# STM32F427 register map
File version: 1.4
CPU: CM4 r0p1, little endian, MPU, FPU, 4 interrupt priority bits
Registers are 32-bit, read-write, reset 0x0 unless marked. A register's access mark holds for its fields unless they carry their own. Offsets are from the block's base; [hi:lo] are bit positions.

## DMA2D
Base 0x4002B000
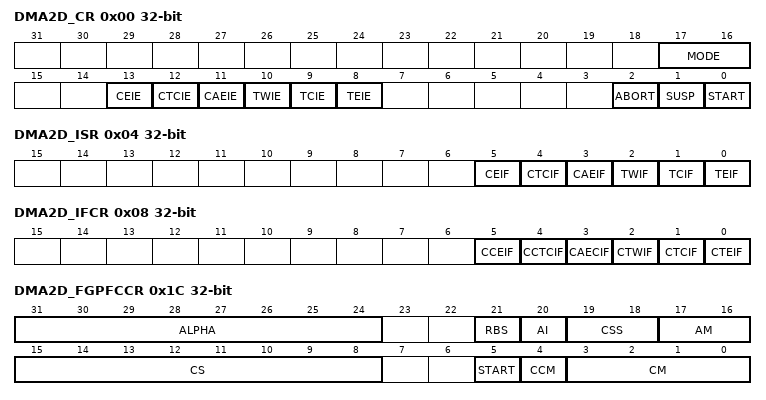
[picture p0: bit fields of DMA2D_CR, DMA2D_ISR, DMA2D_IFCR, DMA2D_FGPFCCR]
0x00 DMA2D_CR — DMA2D control register
  [17:16] MODE — DMA2D mode This bit is set and cleared by software. It cannot be modified while a transfer is ongoing.
  [13] CEIE — Configuration Error Interrupt Enable This bit is set and cleared by software.
  [12] CTCIE — CLUT transfer complete interrupt enable This bit is set and cleared by software.
  [11] CAEIE — CLUT access error interrupt enable This bit is set and cleared by software.
  [10] TWIE — Transfer watermark interrupt enable This bit is set and cleared by software.
  [9] TCIE — Transfer complete interrupt enable This bit is set and cleared by software.
  [8] TEIE — Transfer error interrupt enable This bit is set and cleared by software.
  [2] ABORT — Abort This bit can be used to abort the current transfer. This bit is set by software and is automatically reset by hardware when the START bit is reset.
  [1] SUSP — Suspend This bit can be used to suspend the current transfer. This bit is set and reset by software. It is automatically reset by hardware when the START bit is reset.
  [0] START — Start This bit can be used to launch the DMA2D according to the parameters loaded in the various configuration registers. This bit is automatically reset by the following events: ** At the end of the transfer ** When the data transfer is aborted by the user application by setting the ABORT bit in DMA2D_CR ** When a data transfer error occurs ** When the data transfer has not started due to a configuration error or another transfer operation already ongoing (automatic CLUT loading).
0x04 DMA2D_ISR ro — DMA2D Interrupt Status Register
  [5] CEIF — Configuration error interrupt flag This bit is set when the START bit of DMA2D_CR, DMA2DFGPFCCR or DMA2D_BGPFCCR is set and a wrong configuration has been programmed.
  [4] CTCIF — CLUT transfer complete interrupt flag This bit is set when the CLUT copy from a system memory area to the internal DMA2D memory is complete.
  [3] CAEIF — CLUT access error interrupt flag This bit is set when the CPU accesses the CLUT while the CLUT is being automatically copied from a system memory to the internal DMA2D.
  [2] TWIF — Transfer watermark interrupt flag This bit is set when the last pixel of the watermarked line has been transferred.
  [1] TCIF — Transfer complete interrupt flag This bit is set when a DMA2D transfer operation is complete (data transfer only).
  [0] TEIF — Transfer error interrupt flag This bit is set when an error occurs during a DMA transfer (data transfer or automatic CLUT loading).
0x08 DMA2D_IFCR — DMA2D interrupt flag clear register
  [5] CCEIF — Clear configuration error interrupt flag Programming this bit to 1 clears the CEIF flag in the DMA2D_ISR register
  [4] CCTCIF — Clear CLUT transfer complete interrupt flag Programming this bit to 1 clears the CTCIF flag in the DMA2D_ISR register
  [3] CAECIF — Clear CLUT access error interrupt flag Programming this bit to 1 clears the CAEIF flag in the DMA2D_ISR register
  [2] CTWIF — Clear transfer watermark interrupt flag Programming this bit to 1 clears the TWIF flag in the DMA2D_ISR register
  [1] CTCIF — Clear transfer complete interrupt flag Programming this bit to 1 clears the TCIF flag in the DMA2D_ISR register
  [0] CTEIF — Clear Transfer error interrupt flag Programming this bit to 1 clears the TEIF flag in the DMA2D_ISR register
0x0C DMA2D_FGMAR — DMA2D foreground memory address register
  [31:0] MA — Memory address Address of the data used for the foreground image. This register can only be written when data transfers are disabled. Once the data transfer has started, this register is read-only. The address alignment must match the image format selected e.g. a 32-bit per pixel format must be 32-bit aligned, a 16-bit per pixel format must be 16-bit aligned and a 4-bit per pixel format must be 8-bit aligned.
0x10 DMA2D_FGOR — DMA2D foreground offset register
  [13:0] LO — Line offset Line offset used for the foreground expressed in pixel. This value is used to generate the address. It is added at the end of each line to determine the starting address of the next line. These bits can only be written when data transfers are disabled. Once a data transfer has started, they become read-only. If the image format is 4-bit per pixel, the line offset must be even.
0x14 DMA2D_BGMAR — DMA2D background memory address register
  [31:0] MA — Memory address Address of the data used for the background image. This register can only be written when data transfers are disabled. Once a data transfer has started, this register is read-only. The address alignment must match the image format selected e.g. a 32-bit per pixel format must be 32-bit aligned, a 16-bit per pixel format must be 16-bit aligned and a 4-bit per pixel format must be 8-bit aligned.
0x18 DMA2D_BGOR — DMA2D background offset register
  [13:0] LO — Line offset Line offset used for the background image (expressed in pixel). This value is used for the address generation. It is added at the end of each line to determine the starting address of the next line. These bits can only be written when data transfers are disabled. Once data transfer has started, they become read-only. If the image format is 4-bit per pixel, the line offset must be even.
0x1C DMA2D_FGPFCCR — DMA2D foreground PFC control register
  [31:24] ALPHA — Alpha value These bits define a fixed alpha channel value which can replace the original alpha value or be multiplied by the original alpha value according to the alpha mode selected through the AM[1:0] bits. These bits can only be written when data transfers are disabled. Once a transfer has started, they become read-only.
  [21] RBS — Red Blue Swap This bit allows to swap the R & B to support BGR or ABGR color formats. Once the transfer has started, this bit is read-only.
  [20] AI — Alpha Inverted This bit inverts the alpha value. Once the transfer has started, this bit is read-only.
  [19:18] CSS — Chroma Sub-Sampling These bits define the chroma sub-sampling mode for YCbCr color mode. Once the transfer has started, these bits are read-only. others: meaningless
  [17:16] AM — Alpha mode These bits select the alpha channel value to be used for the foreground image. They can only be written data the transfer are disabled. Once the transfer has started, they become read-only. other configurations are meaningless
  [15:8] CS — CLUT size These bits define the size of the CLUT used for the foreground image. Once the CLUT transfer has started, this field is read-only. The number of CLUT entries is equal to CS[7:0] + 1.
  [5] START — Start This bit can be set to start the automatic loading of the CLUT. It is automatically reset: ** at the end of the transfer ** when the transfer is aborted by the user application by setting the ABORT bit in DMA2D_CR ** when a transfer error occurs ** when the transfer has not started due to a configuration error or another transfer operation already ongoing (data transfer or automatic background CLUT transfer).
  [4] CCM — CLUT color mode This bit defines the color format of the CLUT. It can only be written when the transfer is disabled. Once the CLUT transfer has started, this bit is read-only.
  [3:0] CM — Color mode These bits defines the color format of the foreground image. They can only be written when data transfers are disabled. Once the transfer has started, they are read-only. others: meaningless
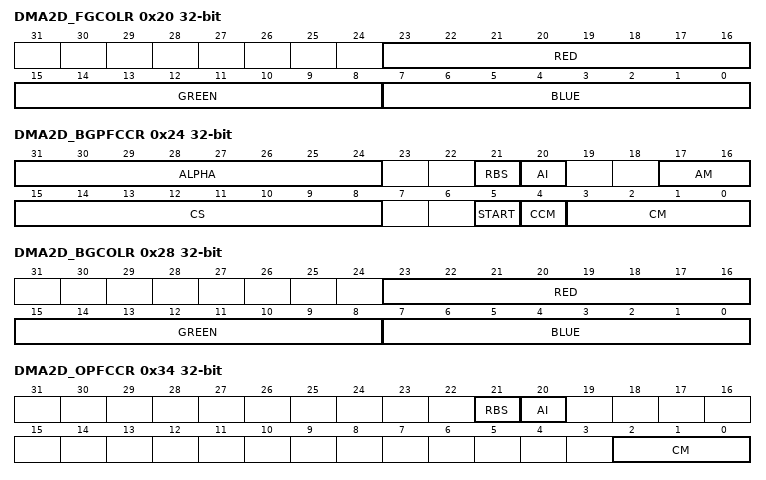
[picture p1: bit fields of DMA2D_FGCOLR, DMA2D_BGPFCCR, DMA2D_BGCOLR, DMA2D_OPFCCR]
0x20 DMA2D_FGCOLR — DMA2D foreground color register
  [23:16] RED — Red Value These bits defines the red value for the A4 or A8 mode of the foreground image. They can only be written when data transfers are disabled. Once the transfer has started, they are read-only.
  [15:8] GREEN — Green Value These bits defines the green value for the A4 or A8 mode of the foreground image. They can only be written when data transfers are disabled. Once the transfer has started, They are read-only.
  [7:0] BLUE — Blue Value These bits defines the blue value for the A4 or A8 mode of the foreground image. They can only be written when data transfers are disabled. Once the transfer has started, They are read-only.
0x24 DMA2D_BGPFCCR — DMA2D background PFC control register
  [31:24] ALPHA — Alpha value These bits define a fixed alpha channel value which can replace the original alpha value or be multiplied with the original alpha value according to the alpha mode selected with bits AM[1: 0]. These bits can only be written when data transfers are disabled. Once the transfer has started, they are read-only.
  [21] RBS — Red Blue Swap This bit allows to swap the R & B to support BGR or ABGR color formats. Once the transfer has started, this bit is read-only.
  [20] AI — Alpha Inverted This bit inverts the alpha value. Once the transfer has started, this bit is read-only.
  [17:16] AM — Alpha mode These bits define which alpha channel value to be used for the background image. These bits can only be written when data transfers are disabled. Once the transfer has started, they are read-only. others: meaningless
  [15:8] CS — CLUT size These bits define the size of the CLUT used for the BG. Once the CLUT transfer has started, this field is read-only. The number of CLUT entries is equal to CS[7:0] + 1.
  [5] START — Start This bit is set to start the automatic loading of the CLUT. This bit is automatically reset: ** at the end of the transfer ** when the transfer is aborted by the user application by setting the ABORT bit in the DMA2D_CR ** when a transfer error occurs ** when the transfer has not started due to a configuration error or another transfer operation already on going (data transfer or automatic BackGround CLUT transfer).
  [4] CCM — CLUT Color mode These bits define the color format of the CLUT. This register can only be written when the transfer is disabled. Once the CLUT transfer has started, this bit is read-only.
  [3:0] CM — Color mode These bits define the color format of the foreground image. These bits can only be written when data transfers are disabled. Once the transfer has started, they are read-only. others: meaningless
0x28 DMA2D_BGCOLR — DMA2D background color register
  [23:16] RED — Red Value These bits define the red value for the A4 or A8 mode of the background. These bits can only be written when data transfers are disabled. Once the transfer has started, they are read-only.
  [15:8] GREEN — Green Value These bits define the green value for the A4 or A8 mode of the background. These bits can only be written when data transfers are disabled. Once the transfer has started, they are read-only.
  [7:0] BLUE — Blue Value These bits define the blue value for the A4 or A8 mode of the background. These bits can only be written when data transfers are disabled. Once the transfer has started, they are read-only.
0x2C DMA2D_FGCMAR — DMA2D foreground CLUT memory address register
  [31:0] MA — Memory Address Address of the data used for the CLUT address dedicated to the foreground image. This register can only be written when no transfer is ongoing. Once the CLUT transfer has started, this register is read-only. If the foreground CLUT format is 32-bit, the address must be 32-bit aligned.
0x30 DMA2D_BGCMAR — DMA2D background CLUT memory address register
  [31:0] MA — Memory address Address of the data used for the CLUT address dedicated to the background image. This register can only be written when no transfer is on going. Once the CLUT transfer has started, this register is read-only. If the background CLUT format is 32-bit, the address must be 32-bit aligned.
0x34 DMA2D_OPFCCR — DMA2D output PFC control register
  [21] RBS — Red Blue Swap This bit allows to swap the R & B to support BGR or ABGR color formats. Once the transfer has started, this bit is read-only.
  [20] AI — Alpha Inverted This bit inverts the alpha value. Once the transfer has started, this bit is read-only.
  [2:0] CM — Color mode These bits define the color format of the output image. These bits can only be written when data transfers are disabled. Once the transfer has started, they are read-only. others: meaningless
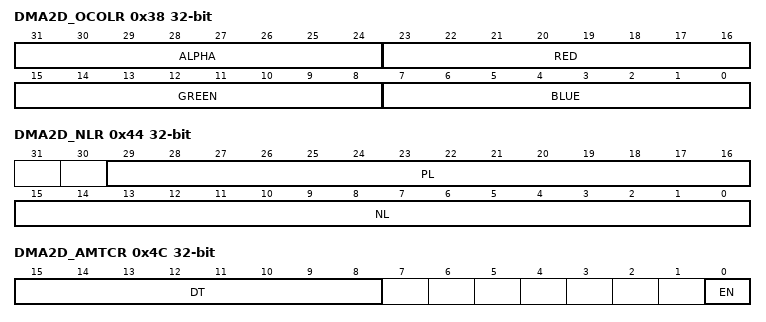
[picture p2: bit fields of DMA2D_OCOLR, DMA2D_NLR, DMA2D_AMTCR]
0x38 DMA2D_OCOLR — DMA2D output color register
  [31:24] ALPHA — Alpha Channel Value These bits define the alpha channel of the output color. These bits can only be written when data transfers are disabled. Once the transfer has started, they are read-only.
  [23:16] RED — Red Value These bits define the red value of the output image. These bits can only be written when data transfers are disabled. Once the transfer has started, they are read-only.
  [15:8] GREEN — Green Value These bits define the green value of the output image. These bits can only be written when data transfers are disabled. Once the transfer has started, they are read-only.
  [7:0] BLUE — Blue Value These bits define the blue value of the output image. These bits can only be written when data transfers are disabled. Once the transfer has started, they are read-only.
0x3C DMA2D_OMAR — DMA2D output memory address register
  [31:0] MA — Memory Address Address of the data used for the output FIFO. These bits can only be written when data transfers are disabled. Once the transfer has started, they are read-only. The address alignment must match the image format selected e.g. a 32-bit per pixel format must be 32-bit aligned and a 16-bit per pixel format must be 16-bit aligned.
0x40 DMA2D_OOR — DMA2D output offset register
  [13:0] LO — Line Offset Line offset used for the output (expressed in pixels). This value is used for the address generation. It is added at the end of each line to determine the starting address of the next line. These bits can only be written when data transfers are disabled. Once the transfer has started, they are read-only.
0x44 DMA2D_NLR — DMA2D number of line register
  [29:16] PL — Pixel per lines Number of pixels per lines of the area to be transferred. These bits can only be written when data transfers are disabled. Once the transfer has started, they are read-only. If any of the input image format is 4-bit per pixel, pixel per lines must be even.
  [15:0] NL — Number of lines Number of lines of the area to be transferred. These bits can only be written when data transfers are disabled. Once the transfer has started, they are read-only.
0x48 DMA2D_LWR — DMA2D line watermark register
  [15:0] LW — Line watermark These bits allow to configure the line watermark for interrupt generation. An interrupt is raised when the last pixel of the watermarked line has been transferred. These bits can only be written when data transfers are disabled. Once the transfer has started, they are read-only.
0x4C DMA2D_AMTCR — DMA2D AXI master timer configuration register
  [15:8] DT — Dead Time Dead time value in the AXI clock cycle inserted between two consecutive accesses on the AXI master port. These bits represent the minimum guaranteed number of cycles between two consecutive AXI accesses.
  [0] EN — Enable Enables the dead time functionality.
